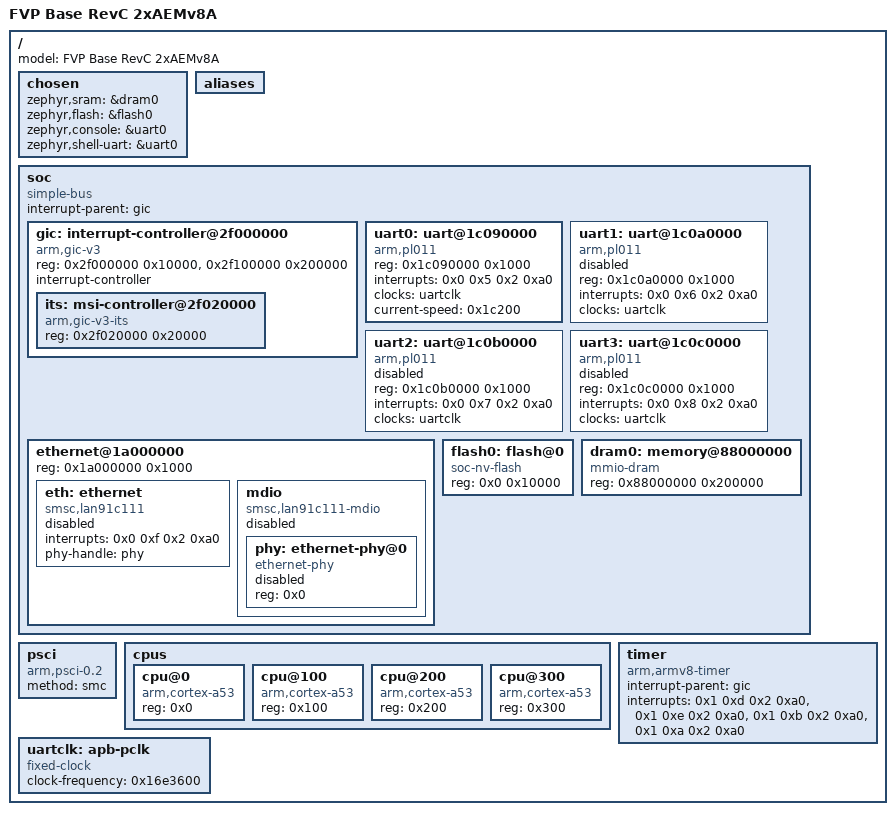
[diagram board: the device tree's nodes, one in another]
/dts-v1/;

/* node '/' defined in zephyr/dts/common/skeleton.dtsi:9 */
/ {
	#address-cells = < 0x1 >;         /* in zephyr/dts/common/skeleton.dtsi:10 */
	#size-cells = < 0x1 >;            /* in zephyr/dts/common/skeleton.dtsi:11 */
	model = "FVP Base RevC 2xAEMv8A"; /* in zephyr/boards/arm/fvp_base_revc_2xaemv8a/fvp_base_revc_2xaemv8a.dts:13 */

	/* node '/chosen' defined in zephyr/dts/common/skeleton.dtsi:13 */
	chosen {
		zephyr,sram = &dram0;       /* in zephyr/boards/arm/fvp_base_revc_2xaemv8a/fvp_base_revc_2xaemv8a.dts:20 */
		zephyr,flash = &flash0;     /* in zephyr/boards/arm/fvp_base_revc_2xaemv8a/fvp_base_revc_2xaemv8a.dts:21 */
		zephyr,console = &uart0;    /* in zephyr/boards/arm/fvp_base_revc_2xaemv8a/fvp_base_revc_2xaemv8a.dts:22 */
		zephyr,shell-uart = &uart0; /* in zephyr/boards/arm/fvp_base_revc_2xaemv8a/fvp_base_revc_2xaemv8a.dts:23 */
	};

	/* node '/aliases' defined in zephyr/dts/common/skeleton.dtsi:15 */
	aliases {
	};

	/* node '/soc' defined in zephyr/dts/arm64/armv8-a.dtsi:10 */
	soc {
		#address-cells = < 0x1 >;    /* in zephyr/dts/arm64/armv8-a.dtsi:11 */
		#size-cells = < 0x1 >;       /* in zephyr/dts/arm64/armv8-a.dtsi:12 */
		compatible = "simple-bus";   /* in zephyr/dts/arm64/armv8-a.dtsi:13 */
		ranges;                      /* in zephyr/dts/arm64/armv8-a.dtsi:14 */
		interrupt-parent = < &gic >; /* in zephyr/boards/arm/fvp_base_revc_2xaemv8a/fvp_base_revc_2xaemv8a.dts:80 */

		/* node '/soc/interrupt-controller@2f000000' defined in zephyr/boards/arm/fvp_base_revc_2xaemv8a/fvp_base_revc_2xaemv8a.dts:82 */
		gic: interrupt-controller@2f000000 {
			compatible = "arm,gic-v3",
			             "arm,gic";        /* in zephyr/boards/arm/fvp_base_revc_2xaemv8a/fvp_base_revc_2xaemv8a.dts:83 */
			reg = < 0x2f000000 0x10000 >,
			      < 0x2f100000 0x200000 >; /* in zephyr/boards/arm/fvp_base_revc_2xaemv8a/fvp_base_revc_2xaemv8a.dts:84 */
			interrupt-controller;          /* in zephyr/boards/arm/fvp_base_revc_2xaemv8a/fvp_base_revc_2xaemv8a.dts:86 */
			#interrupt-cells = < 0x4 >;    /* in zephyr/boards/arm/fvp_base_revc_2xaemv8a/fvp_base_revc_2xaemv8a.dts:87 */
			status = "okay";               /* in zephyr/boards/arm/fvp_base_revc_2xaemv8a/fvp_base_revc_2xaemv8a.dts:88 */
			#address-cells = < 0x1 >;      /* in zephyr/boards/arm/fvp_base_revc_2xaemv8a/fvp_base_revc_2xaemv8a.dts:89 */
			#size-cells = < 0x1 >;         /* in zephyr/boards/arm/fvp_base_revc_2xaemv8a/fvp_base_revc_2xaemv8a.dts:90 */
			phandle = < 0x1 >;             /* in zephyr/boards/arm/fvp_base_revc_2xaemv8a/fvp_base_revc_2xaemv8a.dts:80 */

			/* node '/soc/interrupt-controller@2f000000/msi-controller@2f020000' defined in zephyr/boards/arm/fvp_base_revc_2xaemv8a/fvp_base_revc_2xaemv8a.dts:92 */
			its: msi-controller@2f020000 {
				compatible = "arm,gic-v3-its"; /* in zephyr/boards/arm/fvp_base_revc_2xaemv8a/fvp_base_revc_2xaemv8a.dts:93 */
				reg = < 0x2f020000 0x20000 >;  /* in zephyr/boards/arm/fvp_base_revc_2xaemv8a/fvp_base_revc_2xaemv8a.dts:94 */
				status = "okay";               /* in zephyr/boards/arm/fvp_base_revc_2xaemv8a/fvp_base_revc_2xaemv8a.dts:95 */
			};
		};

		/* node '/soc/uart@1c090000' defined in zephyr/boards/arm/fvp_base_revc_2xaemv8a/fvp_base_revc_2xaemv8a.dts:99 */
		uart0: uart@1c090000 {
			compatible = "arm,pl011";          /* in zephyr/boards/arm/fvp_base_revc_2xaemv8a/fvp_base_revc_2xaemv8a.dts:100 */
			reg = < 0x1c090000 0x1000 >;       /* in zephyr/boards/arm/fvp_base_revc_2xaemv8a/fvp_base_revc_2xaemv8a.dts:101 */
			interrupts = < 0x0 0x5 0x2 0xa0 >; /* in zephyr/boards/arm/fvp_base_revc_2xaemv8a/fvp_base_revc_2xaemv8a.dts:103 */
			interrupt-names = "irq_5";         /* in zephyr/boards/arm/fvp_base_revc_2xaemv8a/fvp_base_revc_2xaemv8a.dts:104 */
			clocks = < &uartclk >;             /* in zephyr/boards/arm/fvp_base_revc_2xaemv8a/fvp_base_revc_2xaemv8a.dts:105 */
			status = "okay";                   /* in zephyr/boards/arm/fvp_base_revc_2xaemv8a/fvp_base_revc_2xaemv8a.dts:173 */
			current-speed = < 0x1c200 >;       /* in zephyr/boards/arm/fvp_base_revc_2xaemv8a/fvp_base_revc_2xaemv8a.dts:174 */
		};

		/* node '/soc/uart@1c0a0000' defined in zephyr/boards/arm/fvp_base_revc_2xaemv8a/fvp_base_revc_2xaemv8a.dts:108 */
		uart1: uart@1c0a0000 {
			compatible = "arm,pl011";          /* in zephyr/boards/arm/fvp_base_revc_2xaemv8a/fvp_base_revc_2xaemv8a.dts:109 */
			reg = < 0x1c0a0000 0x1000 >;       /* in zephyr/boards/arm/fvp_base_revc_2xaemv8a/fvp_base_revc_2xaemv8a.dts:110 */
			status = "disabled";               /* in zephyr/boards/arm/fvp_base_revc_2xaemv8a/fvp_base_revc_2xaemv8a.dts:111 */
			interrupts = < 0x0 0x6 0x2 0xa0 >; /* in zephyr/boards/arm/fvp_base_revc_2xaemv8a/fvp_base_revc_2xaemv8a.dts:112 */
			interrupt-names = "irq_6";         /* in zephyr/boards/arm/fvp_base_revc_2xaemv8a/fvp_base_revc_2xaemv8a.dts:113 */
			clocks = < &uartclk >;             /* in zephyr/boards/arm/fvp_base_revc_2xaemv8a/fvp_base_revc_2xaemv8a.dts:114 */
		};

		/* node '/soc/uart@1c0b0000' defined in zephyr/boards/arm/fvp_base_revc_2xaemv8a/fvp_base_revc_2xaemv8a.dts:117 */
		uart2: uart@1c0b0000 {
			compatible = "arm,pl011";          /* in zephyr/boards/arm/fvp_base_revc_2xaemv8a/fvp_base_revc_2xaemv8a.dts:118 */
			reg = < 0x1c0b0000 0x1000 >;       /* in zephyr/boards/arm/fvp_base_revc_2xaemv8a/fvp_base_revc_2xaemv8a.dts:119 */
			status = "disabled";               /* in zephyr/boards/arm/fvp_base_revc_2xaemv8a/fvp_base_revc_2xaemv8a.dts:120 */
			interrupts = < 0x0 0x7 0x2 0xa0 >; /* in zephyr/boards/arm/fvp_base_revc_2xaemv8a/fvp_base_revc_2xaemv8a.dts:121 */
			interrupt-names = "irq_7";         /* in zephyr/boards/arm/fvp_base_revc_2xaemv8a/fvp_base_revc_2xaemv8a.dts:122 */
			clocks = < &uartclk >;             /* in zephyr/boards/arm/fvp_base_revc_2xaemv8a/fvp_base_revc_2xaemv8a.dts:123 */
		};

		/* node '/soc/uart@1c0c0000' defined in zephyr/boards/arm/fvp_base_revc_2xaemv8a/fvp_base_revc_2xaemv8a.dts:126 */
		uart3: uart@1c0c0000 {
			compatible = "arm,pl011";          /* in zephyr/boards/arm/fvp_base_revc_2xaemv8a/fvp_base_revc_2xaemv8a.dts:127 */
			reg = < 0x1c0c0000 0x1000 >;       /* in zephyr/boards/arm/fvp_base_revc_2xaemv8a/fvp_base_revc_2xaemv8a.dts:128 */
			status = "disabled";               /* in zephyr/boards/arm/fvp_base_revc_2xaemv8a/fvp_base_revc_2xaemv8a.dts:129 */
			interrupts = < 0x0 0x8 0x2 0xa0 >; /* in zephyr/boards/arm/fvp_base_revc_2xaemv8a/fvp_base_revc_2xaemv8a.dts:130 */
			interrupt-names = "irq_8";         /* in zephyr/boards/arm/fvp_base_revc_2xaemv8a/fvp_base_revc_2xaemv8a.dts:131 */
			clocks = < &uartclk >;             /* in zephyr/boards/arm/fvp_base_revc_2xaemv8a/fvp_base_revc_2xaemv8a.dts:132 */
		};

		/* node '/soc/ethernet@1a000000' defined in zephyr/boards/arm/fvp_base_revc_2xaemv8a/fvp_base_revc_2xaemv8a.dts:135 */
		ethernet@1a000000 {
			reg = < 0x1a000000 0x1000 >; /* in zephyr/boards/arm/fvp_base_revc_2xaemv8a/fvp_base_revc_2xaemv8a.dts:136 */

			/* node '/soc/ethernet@1a000000/ethernet' defined in zephyr/boards/arm/fvp_base_revc_2xaemv8a/fvp_base_revc_2xaemv8a.dts:138 */
			eth: ethernet {
				compatible = "smsc,lan91c111";     /* in zephyr/boards/arm/fvp_base_revc_2xaemv8a/fvp_base_revc_2xaemv8a.dts:139 */
				interrupts = < 0x0 0xf 0x2 0xa0 >; /* in zephyr/boards/arm/fvp_base_revc_2xaemv8a/fvp_base_revc_2xaemv8a.dts:140 */
				status = "disabled";               /* in zephyr/boards/arm/fvp_base_revc_2xaemv8a/fvp_base_revc_2xaemv8a.dts:141 */
				phy-handle = < &phy >;             /* in zephyr/boards/arm/fvp_base_revc_2xaemv8a/fvp_base_revc_2xaemv8a.dts:143 */
			};

			/* node '/soc/ethernet@1a000000/mdio' defined in zephyr/boards/arm/fvp_base_revc_2xaemv8a/fvp_base_revc_2xaemv8a.dts:146 */
			mdio: mdio {
				compatible = "smsc,lan91c111-mdio"; /* in zephyr/boards/arm/fvp_base_revc_2xaemv8a/fvp_base_revc_2xaemv8a.dts:147 */
				status = "disabled";                /* in zephyr/boards/arm/fvp_base_revc_2xaemv8a/fvp_base_revc_2xaemv8a.dts:148 */
				#address-cells = < 0x1 >;           /* in zephyr/boards/arm/fvp_base_revc_2xaemv8a/fvp_base_revc_2xaemv8a.dts:149 */
				#size-cells = < 0x0 >;              /* in zephyr/boards/arm/fvp_base_revc_2xaemv8a/fvp_base_revc_2xaemv8a.dts:150 */

				/* node '/soc/ethernet@1a000000/mdio/ethernet-phy@0' defined in zephyr/boards/arm/fvp_base_revc_2xaemv8a/fvp_base_revc_2xaemv8a.dts:152 */
				phy: ethernet-phy@0 {
					compatible = "ethernet-phy"; /* in zephyr/boards/arm/fvp_base_revc_2xaemv8a/fvp_base_revc_2xaemv8a.dts:153 */
					status = "disabled";         /* in zephyr/boards/arm/fvp_base_revc_2xaemv8a/fvp_base_revc_2xaemv8a.dts:154 */
					reg = < 0x0 >;               /* in zephyr/boards/arm/fvp_base_revc_2xaemv8a/fvp_base_revc_2xaemv8a.dts:155 */
					phandle = < 0x3 >;           /* in zephyr/boards/arm/fvp_base_revc_2xaemv8a/fvp_base_revc_2xaemv8a.dts:143 */
				};
			};
		};

		/* node '/soc/flash@0' defined in zephyr/boards/arm/fvp_base_revc_2xaemv8a/fvp_base_revc_2xaemv8a.dts:160 */
		flash0: flash@0 {
			compatible = "soc-nv-flash"; /* in zephyr/boards/arm/fvp_base_revc_2xaemv8a/fvp_base_revc_2xaemv8a.dts:161 */
			reg = < 0x0 0x10000 >;       /* in zephyr/boards/arm/fvp_base_revc_2xaemv8a/fvp_base_revc_2xaemv8a.dts:162 */
		};

		/* node '/soc/memory@88000000' defined in zephyr/boards/arm/fvp_base_revc_2xaemv8a/fvp_base_revc_2xaemv8a.dts:165 */
		dram0: memory@88000000 {
			compatible = "mmio-dram";      /* in zephyr/boards/arm/fvp_base_revc_2xaemv8a/fvp_base_revc_2xaemv8a.dts:166 */
			reg = < 0x88000000 0x200000 >; /* in zephyr/boards/arm/fvp_base_revc_2xaemv8a/fvp_base_revc_2xaemv8a.dts:167 */
		};
	};

	/* node '/psci' defined in zephyr/boards/arm/fvp_base_revc_2xaemv8a/fvp_base_revc_2xaemv8a.dts:26 */
	psci {
		compatible = "arm,psci-0.2"; /* in zephyr/boards/arm/fvp_base_revc_2xaemv8a/fvp_base_revc_2xaemv8a.dts:27 */
		method = "smc";              /* in zephyr/boards/arm/fvp_base_revc_2xaemv8a/fvp_base_revc_2xaemv8a.dts:28 */
	};

	/* node '/cpus' defined in zephyr/boards/arm/fvp_base_revc_2xaemv8a/fvp_base_revc_2xaemv8a.dts:31 */
	cpus {
		#address-cells = < 0x1 >; /* in zephyr/boards/arm/fvp_base_revc_2xaemv8a/fvp_base_revc_2xaemv8a.dts:32 */
		#size-cells = < 0x0 >;    /* in zephyr/boards/arm/fvp_base_revc_2xaemv8a/fvp_base_revc_2xaemv8a.dts:33 */

		/* node '/cpus/cpu@0' defined in zephyr/boards/arm/fvp_base_revc_2xaemv8a/fvp_base_revc_2xaemv8a.dts:35 */
		cpu@0 {
			device_type = "cpu";           /* in zephyr/boards/arm/fvp_base_revc_2xaemv8a/fvp_base_revc_2xaemv8a.dts:36 */
			compatible = "arm,cortex-a53"; /* in zephyr/boards/arm/fvp_base_revc_2xaemv8a/fvp_base_revc_2xaemv8a.dts:37 */
			reg = < 0x0 >;                 /* in zephyr/boards/arm/fvp_base_revc_2xaemv8a/fvp_base_revc_2xaemv8a.dts:38 */
		};

		/* node '/cpus/cpu@100' defined in zephyr/boards/arm/fvp_base_revc_2xaemv8a/fvp_base_revc_2xaemv8a.dts:41 */
		cpu@100 {
			device_type = "cpu";           /* in zephyr/boards/arm/fvp_base_revc_2xaemv8a/fvp_base_revc_2xaemv8a.dts:42 */
			compatible = "arm,cortex-a53"; /* in zephyr/boards/arm/fvp_base_revc_2xaemv8a/fvp_base_revc_2xaemv8a.dts:43 */
			reg = < 0x100 >;               /* in zephyr/boards/arm/fvp_base_revc_2xaemv8a/fvp_base_revc_2xaemv8a.dts:44 */
		};

		/* node '/cpus/cpu@200' defined in zephyr/boards/arm/fvp_base_revc_2xaemv8a/fvp_base_revc_2xaemv8a.dts:47 */
		cpu@200 {
			device_type = "cpu";           /* in zephyr/boards/arm/fvp_base_revc_2xaemv8a/fvp_base_revc_2xaemv8a.dts:48 */
			compatible = "arm,cortex-a53"; /* in zephyr/boards/arm/fvp_base_revc_2xaemv8a/fvp_base_revc_2xaemv8a.dts:49 */
			reg = < 0x200 >;               /* in zephyr/boards/arm/fvp_base_revc_2xaemv8a/fvp_base_revc_2xaemv8a.dts:50 */
		};

		/* node '/cpus/cpu@300' defined in zephyr/boards/arm/fvp_base_revc_2xaemv8a/fvp_base_revc_2xaemv8a.dts:53 */
		cpu@300 {
			device_type = "cpu";           /* in zephyr/boards/arm/fvp_base_revc_2xaemv8a/fvp_base_revc_2xaemv8a.dts:54 */
			compatible = "arm,cortex-a53"; /* in zephyr/boards/arm/fvp_base_revc_2xaemv8a/fvp_base_revc_2xaemv8a.dts:55 */
			reg = < 0x300 >;               /* in zephyr/boards/arm/fvp_base_revc_2xaemv8a/fvp_base_revc_2xaemv8a.dts:56 */
		};
	};

	/* node '/timer' defined in zephyr/boards/arm/fvp_base_revc_2xaemv8a/fvp_base_revc_2xaemv8a.dts:60 */
	timer {
		compatible = "arm,armv8-timer";    /* in zephyr/boards/arm/fvp_base_revc_2xaemv8a/fvp_base_revc_2xaemv8a.dts:61 */
		interrupt-parent = < &gic >;       /* in zephyr/boards/arm/fvp_base_revc_2xaemv8a/fvp_base_revc_2xaemv8a.dts:62 */
		interrupts = < 0x1 0xd 0x2 0xa0 >,
		             < 0x1 0xe 0x2 0xa0 >,
		             < 0x1 0xb 0x2 0xa0 >,
		             < 0x1 0xa 0x2 0xa0 >; /* in zephyr/boards/arm/fvp_base_revc_2xaemv8a/fvp_base_revc_2xaemv8a.dts:63 */
	};

	/* node '/apb-pclk' defined in zephyr/boards/arm/fvp_base_revc_2xaemv8a/fvp_base_revc_2xaemv8a.dts:73 */
	uartclk: apb-pclk {
		compatible = "fixed-clock";      /* in zephyr/boards/arm/fvp_base_revc_2xaemv8a/fvp_base_revc_2xaemv8a.dts:74 */
		clock-frequency = < 0x16e3600 >; /* in zephyr/boards/arm/fvp_base_revc_2xaemv8a/fvp_base_revc_2xaemv8a.dts:75 */
		#clock-cells = < 0x0 >;          /* in zephyr/boards/arm/fvp_base_revc_2xaemv8a/fvp_base_revc_2xaemv8a.dts:76 */
		phandle = < 0x2 >;               /* in zephyr/boards/arm/fvp_base_revc_2xaemv8a/fvp_base_revc_2xaemv8a.dts:105 */
	};
};
